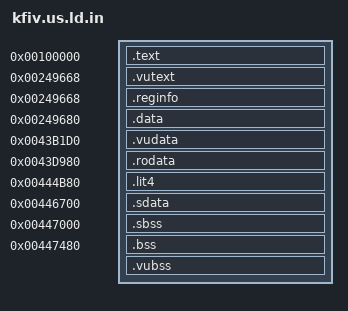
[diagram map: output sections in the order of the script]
/* Linker script for SLUS_203.18 (USA retail), GNU ld 2.10.
 * Output-section addresses are the retail ELF's. tools/gen_ninja.py expands
 * each @INPUTS:<section>@ into that section's inputs in link order and writes
 * build/kfiv.ld (ld 2.10 has no INCLUDE inside an output section). */
ENTRY(_start)
SECTIONS
{
    _gp = 0x0044CB70;
    /* crt0's _start hands _stack, _stack_size and _heap_size to SetupThread
     * and SetupHeap; the values are the retail lui/addiu immediates. */
    _stack = 0x01F00000;
    _stack_size = 0x00100000;
    _heap_size = -1;

    .text    0x00100000 : {
        @INPUTS:text@
    }
    .vutext  0x00249668 : { *(.vutext) }
    .reginfo 0x00249668 : { *(.reginfo) }
    .data    0x00249680 : {
        @INPUTS:data@
    }
    .vudata  0x0043B1D0 : { *(.vudata) }
    .rodata  0x0043D980 : {
        @INPUTS:rodata@
    }
    .lit4    0x00444B80 : {
        @INPUTS:lit4@
    }
    .sdata   0x00446700 : { *(.sdata) }
    _fbss = 0x00447000;
    .sbss    0x00447000 (NOLOAD) : { *(.sbss) *(.scommon) }
    .bss     0x00447480 (NOLOAD) : { *(.bss) *(COMMON) }
    .vubss   . (NOLOAD) : { *(.vubss) }
    _end = .;

    /DISCARD/ : { *(.mdebug) *(.pdr) *(.comment) *(.gnu.attributes) *(.MIPS.abiflags) }
}
